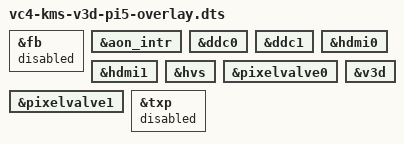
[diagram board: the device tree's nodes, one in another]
/dts-v1/;
/plugin/;

&fb {
	status = "disabled";
};

&aon_intr {
	status = "okay";
};

&ddc0 {
	status = "okay";
};

&ddc1 {
	status = "okay";
};

&hdmi0 {
	status = "okay";
};

&hdmi1 {
	status = "okay";
};

&hvs {
	status = "okay";
};

&pixelvalve0 {
	status = "okay";
};

&pixelvalve1 {
	status = "okay";
};

&txp {
	status = "disabled";
};

&v3d {
	status = "okay";
};
